# STM32WL31 register map
File version: 1.2
CPU: CM0+ r0p0, little endian, MPU, no FPU, 4 interrupt priority bits
Registers are 32-bit, read-write, reset 0x0 unless marked. A register's access mark holds for its fields unless they carry their own. Offsets are from the block's base; [hi:lo] are bit positions; {n}, {i} and the like mark numbered series; 'fields as' and 'values as' point back to an identical list.

## DMA — DMA address block description
Base 0x48700000
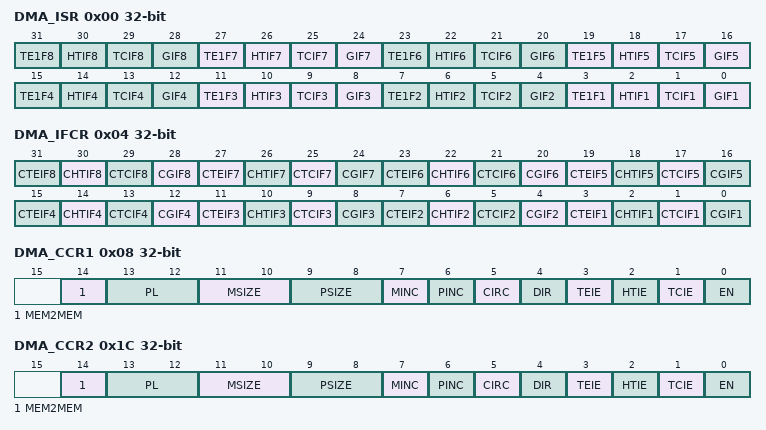
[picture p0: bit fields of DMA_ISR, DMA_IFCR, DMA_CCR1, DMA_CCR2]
0x00 DMA_ISR ro (reset mask 0xFFFF)
  [4n-1] TE1F{n} (n=1..8) — TEIF{n}: Channel {n} transfer error flag This bit is set by hardware. It is cleared by software writing 1 to the corresponding bit in the DMA_IFCR register. 0: No transfer error (TE) on channel {n} 1: A transfer error (TE) occurred on channel {n}
  [4n-2] HTIF{n} (n=1..8) — HTIF{n}: Channel {n} half transfer flag This bit is set by hardware. It is cleared by software writing 1 to the corresponding bit in the DMA_IFCR register. 0: No half transfer (HT) event on channel {n} 1: A half transfer (HT) event occurred on channel {n}
  [4n-3] TCIF{n} (n=1..8) — TCIF{n}: Channel {n} transfer complete flag This bit is set by hardware. It is cleared by software writing 1 to the corresponding bit in the DMA_IFCR register. 0: No transfer complete (TC) event on channel {n} 1: A transfer complete (TC) event occurred on channel {n}
  [4n-4] GIF{n} (n=1..8) — GIF{n}: Channel {n} global interrupt flag This bit is set by hardware. It is cleared by software writing 1 to the corresponding bit in the DMA_IFCR register. 0: No TE, HT or TC event on channel {n} 1: A TE, HT or TC event occurred on channel {n}
0x04 DMA_IFCR wo (reset mask 0xFFFF)
  [4n-1] CTEIF{n} (n=1..8) — CTEIF{n}: Channel {n} transfer error clear This bit is set and cleared by software. 0: No effect 1: Clears the corresponding TEIF flag in the DMA_ISR register
  [30] CHTIF8 — CHTIF8: Channel 8 half transfer clear This bit is set and cleared by software. 0: No effect 1: Clears the corresponding HTIF flag in the DMA_ISR register
  [29] CTCIF8 — CTCIF8: Channel 8 transfer complete clear This bit is set and cleared by software. 0: No effect 1: Clears the corresponding TCIF flag in the DMA_ISR register
  [28] CGIF8 — CGIF8: Channel 8 global interrupt clear This bit is set and cleared by software. 0: No effect 1: Clears the GIF, TEIF, HTIF and TCIF flags in the DMA_ISR register
  [26] CHTIF7 — CHTIF7: Channel 7 half transfer clear This bit is set and cleared by software. 0: No effect 1: Clears the corresponding HTIF flag in the DMA_ISR register
  [25] CTCIF7 — CTCIF7: Channel 7 transfer complete clear This bit is set and cleared by software. 0: No effect 1: Clears the corresponding TCIF flag in the DMA_ISR register
  [24] CGIF7 — CGIF7: Channel 7 global interrupt clear This bit is set and cleared by software. 0: No effect 1: Clears the GIF, TEIF, HTIF and TCIF flags in the DMA_ISR register
  [22] CHTIF6 — CHTIF6: Channel 6 half transfer clear This bit is set and cleared by software. 0: No effect. 1: Clears the corresponding HTIF flag in the DMA_ISR register
  [21] CTCIF6 — CTCIF6: Channel 6 transfer complete clear This bit is set and cleared by software. 0: No effect. 1: Clears the corresponding TCIF flag in the DMA_ISR register
  [20] CGIF6 — CGIF6: Channel 6 global interrupt clear This bit is set and cleared by software. 0: No effect. 1: Clears the GIF, TEIF, HTIF and TCIF flags in the DMA_ISR register
  [18] CHTIF5 — CHTIF5: Channel 5 half transfer clear This bit is set and cleared by software. 0: No effect 1: Clears the corresponding HTIF flag in the DMA_ISR register
  [4n-3] CTCIF{n} (n=1..5) — CTCIF{n}: Channel {n} transfer complete clear This bit is set and cleared by software. 0: No effect 1: Clears the corresponding TCIF flag in the DMA_ISR register
  [4n-4] CGIF{n} (n=1..5) — CGIF{n}: Channel {n} global interrupt clear This bit is set and cleared by software. 0: No effect 1: Clears the GIF, TEIF, HTIF and TCIF flags in the DMA_ISR register
  [14] CHTIF4 — CHTIF4: Channel 4 half transfer clear This bit is set and cleared by software. 0: No effect. 1: Clears the corresponding HTIF flag in the DMA_ISR register
  [10] CHTIF3 — CHTIF3: Channel 3 half transfer clear This bit is set and cleared by software. 0: No effect. 1: Clears the corresponding HTIF flag in the DMA_ISR register
  [6] CHTIF2 — CHTIF2: Channel 2 half transfer clear This bit is set and cleared by software. 0: No effect 1: Clears the corresponding HTIF flag in the DMA_ISR register
  [2] CHTIF1 — CHTIF1: Channel 1 half transfer clear This bit is set and cleared by software. 0: No effect 1: Clears the corresponding HTIF flag in the DMA_ISR register
0x08 DMA_CCR1 — DMA_CCRx register
  [14] MEM2MEM — MEM2MEM: Memory to memory mode This bit is set and cleared by software. 0: Memory to memory mode disabled 1: Memory to memory mode enabled
  [13:12] PL — PL[1:0]: Channel priority level These bits are set and cleared by software. 00: Low 01: Medium 10: High 11: Very high
  [11:10] MSIZE — MSIZE[1:0]: Memory size These bits are set and cleared by software. 00: 8-bits 01: 16-bits 10: 32-bits
  [9:8] PSIZE — PSIZE[1:0]: Peripheral size These bits are set and cleared by software. 00: 8-bits 01: 16-bits 10: 32-bits
  [7] MINC — MINC: Memory increment mode This bit is set and cleared by software. 0: Memory increment mode disabled 1: Memory increment mode enabled
  [6] PINC — PINC: Peripheral increment mode This bit is set and cleared by software. 0: Peripheral increment mode disabled 1: Peripheral increment mode enabled
  [5] CIRC — CIRC: Circular mode This bit is set and cleared by software. 0: Circular mode disabled 1: Circular mode enabled
  [4] DIR — DIR: Data transfer direction This bit is set and cleared by software. 0: Read from peripheral. 1: Read from memory
  [3] TEIE — TEIE: Transfer error interrupt enable This bit is set and cleared by software. 0: TE interrupt disabled 1: TE interrupt enabled
  [2] HTIE — HTIE: Half transfer interrupt enable This bit is set and cleared by software. 0: HT interrupt disabled 1: HT interrupt enabled
  [1] TCIE — TCIE: Transfer complete interrupt enable This bit is set and cleared by software. 0: TC interrupt disabled 1: TC interrupt enabled
  [0] EN — EN: Channel enable This bit is set and cleared by software. 0: Channel disabled 1: Channel enabled
0x0C DMA_CNDTR1 (reset mask 0xF) — DMA_CNDTRx register
  [15:0] NDT — NDT[15:0]: Number of data to transfer Number of data to be transferred (0 up to 65535). This register can only be written when the channel is disabled. Once the channel is enabled, this register is read-only, indicating the remaining bytes to be transmitted. This register decrements after each DMA transfer. Once the transfer is completed, this register can either stay at zero or be reloaded automatically by the value previously programmed if the channel is configured in auto-reload mode. If this register is zero, no transaction can be served whether the channel is enabled or not.
0x10 DMA_CPAR1 (reset mask 0xF) — DMA_CPARx register
  [31:0] PA — PA[31:0]: Peripheral address Base address of the peripheral data register from/to which the data will be read/written. When PSIZE is 01 (16-bit), the PA[0] bit is ignored. Access is automatically aligned to a halfword address. When PSIZE is 10 (32-bit), PA[1:0] are ignored. Access is automatically aligned to a word address.
{0x0+0x14*i} DMA_CMAR{i} (reset mask 0xF) (i=1..8) — DMA_CMARx register
  [31:0] MA — MA[31:0]: Memory address Base address of the memory area from/to which the data will be read/written. When MSIZE is 01 (16-bit), the MA[0] bit is ignored. Access is automatically aligned to a halfword address. When MSIZE is 10 (32-bit), MA[1:0] are ignored. Access is automatically aligned to a word address.
0x1C DMA_CCR2 — DMA_CCRx register
  fields as DMA_CCR1
0x20 DMA_CNDTR2 (reset mask 0xF) — DMA_CNDTRx register
  fields as DMA_CNDTR1
0x24 DMA_CPAR2 (reset mask 0xF) — DMA_CPARx register
  fields as DMA_CPAR1
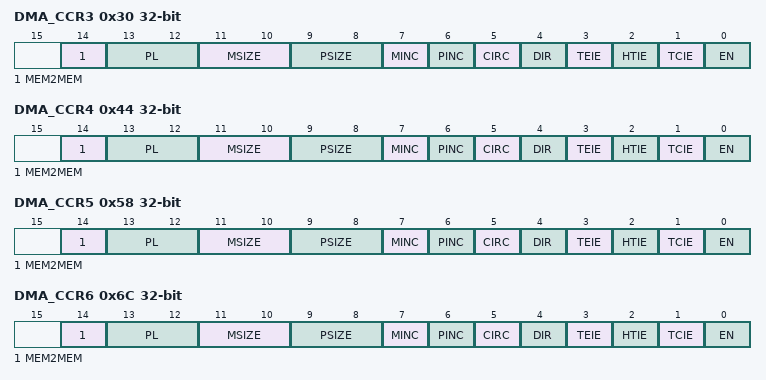
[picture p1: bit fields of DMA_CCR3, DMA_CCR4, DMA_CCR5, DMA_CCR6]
0x30 DMA_CCR3 — DMA_CCRx register
  fields as DMA_CCR1
0x34 DMA_CNDTR3 (reset mask 0xF) — DMA_CNDTRx register
  fields as DMA_CNDTR1
0x38 DMA_CPAR3 (reset mask 0xF) — DMA_CPARx register
  fields as DMA_CPAR1
0x44 DMA_CCR4 — DMA_CCRx register
  fields as DMA_CCR1
0x48 DMA_CNDTR4 (reset mask 0xF) — DMA_CNDTRx register
  fields as DMA_CNDTR1
0x4C DMA_CPAR4 (reset mask 0xF) — DMA_CPARx register
  fields as DMA_CPAR1
0x58 DMA_CCR5 — DMA_CCRx register
  fields as DMA_CCR1
0x5C DMA_CNDTR5 (reset mask 0xF) — DMA_CNDTRx register
  fields as DMA_CNDTR1
0x60 DMA_CPAR5 (reset mask 0xF) — DMA_CPARx register
  fields as DMA_CPAR1
0x6C DMA_CCR6 — DMA_CCRx register
  fields as DMA_CCR1
0x70 DMA_CNDTR6 (reset mask 0xF) — DMA_CNDTRx register
  fields as DMA_CNDTR1
0x74 DMA_CPAR6 (reset mask 0xF) — DMA_CPARx register
  fields as DMA_CPAR1
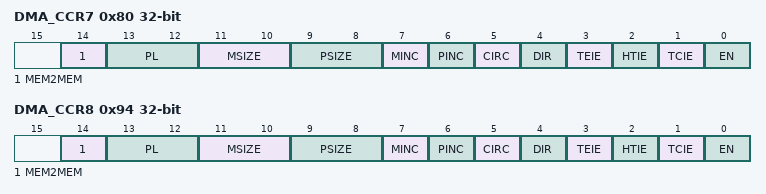
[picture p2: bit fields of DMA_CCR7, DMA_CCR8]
0x80 DMA_CCR7 — DMA_CCRx register
  fields as DMA_CCR1
0x84 DMA_CNDTR7 (reset mask 0xF) — DMA_CNDTRx register
  fields as DMA_CNDTR1
0x88 DMA_CPAR7 (reset mask 0xF) — DMA_CPARx register
  fields as DMA_CPAR1
0x94 DMA_CCR8 — DMA_CCRx register
  fields as DMA_CCR1
0x98 DMA_CNDTR8 (reset mask 0xF) — DMA_CNDTRx register
  fields as DMA_CNDTR1
0x9C DMA_CPAR8 (reset mask 0xF) — DMA_CPARx register
  fields as DMA_CPAR1
